VERSION ""

NS_ :

BS_:

BU_:

BO_ 32 STW2: 8 Vector__XXX

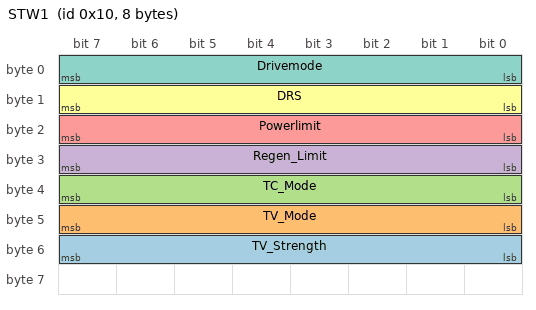
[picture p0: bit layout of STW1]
BO_ 16 STW1: 8 Vector__XXX
 SG_ TV_Strength : 55|8@0+ (1,0) [0|255] "" Vector__XXX
 SG_ TV_Mode : 47|8@0+ (1,0) [0|0] "" Vector__XXX
 SG_ TC_Mode : 39|8@0+ (1,0) [0|0] "" Vector__XXX
 SG_ Regen_Limit : 31|8@0+ (200,0) [0|51000] "" Vector__XXX
 SG_ Powerlimit : 23|8@0+ (200,30000) [30000|81000] "" Vector__XXX
 SG_ DRS : 15|8@0+ (1,0) [0|0] "" Vector__XXX
 SG_ Drivemode : 7|8@0+ (1,0) [0|0] "" Vector__XXX

BA_DEF_ SG_  "GenSigSendType" ENUM  "Cyclic","OnWrite","OnWriteWithRepetition","OnChange","OnChangeWithRepetition","IfActive","IfActiveWithRepetition","NoSigSendType";
BA_DEF_ BO_  "GenMsgSendType" ENUM  "Cyclic","not_used","not_used","not_used","not_used","Cyclic","not_used","IfActive","NoMsgSendType";
BA_DEF_  "DBName" STRING ;
BA_DEF_  "BusType" STRING ;
BA_DEF_DEF_  "GenSigSendType" "Cyclic";
BA_DEF_DEF_  "GenMsgSendType" "NoMsgSendType";
BA_DEF_DEF_  "DBName" "";
BA_DEF_DEF_  "BusType" "CAN";
BA_ "DBName" "JR23_CANdb_to_VCU";
